# Display_Controller_VID2 register map
Vendor: Texas Instruments
Peripheral module from a debugger description file (folder omap36xx).
Registers are 32-bit, read-write, reset 0x0 unless marked. A register's access mark holds for its fields unless they carry their own. Offsets are as the file gives them; lines under a group give offsets from that group; [hi:lo] are bit positions; {n}, {i} and the like mark numbered series; 'fields as' and 'values as' point back to an identical list; <NAME> marks a mode.

## Display_Controller_VID2
0x14C DISPC_VIDn_BAj_0 — The register configures the base address of the video buffer for video window #n(#j for ping-pong mechanism with external trigger, based on the field polarity: 0 for even field and 1 for odd field).Shadow register, updated on VFP start period or EVSYNC.
  [31:0] VIDBA — Video base addressBase address of the video buffer (aligned on pixel size boundary)
0x150 DISPC_VIDn_BAj_1 — The register configures the base address of the video buffer for video window #n(#j for ping-pong mechanism with external trigger, based on the field polarity: 0 for even field and 1 for odd field).Shadow register, updated on VFP start period or EVSYNC.
  fields as DISPC_VIDn_BAj_0
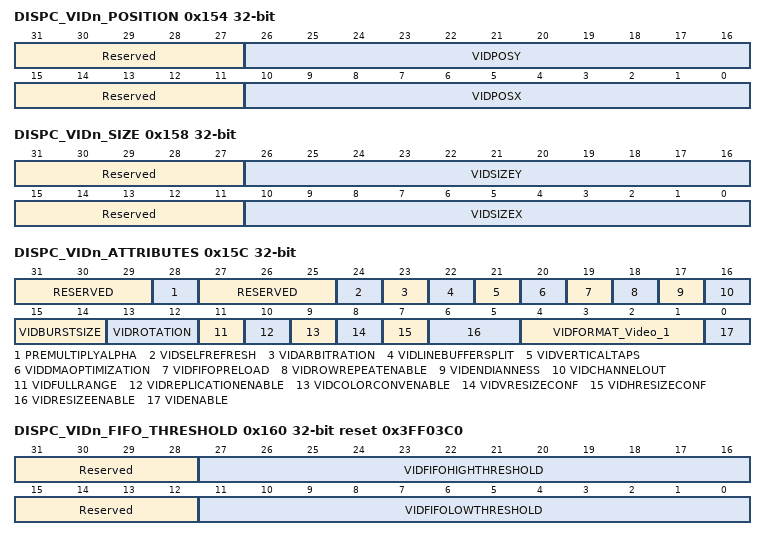
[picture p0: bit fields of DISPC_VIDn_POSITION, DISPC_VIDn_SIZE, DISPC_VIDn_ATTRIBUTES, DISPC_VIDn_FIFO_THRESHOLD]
0x154 DISPC_VIDn_POSITION — The register configures the position of video window #n.Shadow register, updated on VFP start period or EVSYNC.
  [31:27] Reserved — Write 0s for future compatibility.Read returns 0
  [26:16] VIDPOSY — Y position of video window #nEncoded value (from 0 to 2047) to specify the Y position of video window #n. The line at the top has the Y-position 0.
  [15:11] Reserved — Write 0s for future compatibility.Read returns 0
  [10:0] VIDPOSX — X position of video window #nEncoded value (from 0 to 2047) to specify the X position of video window #n. The first pixel on the left of the display screen has the X-position 0.
0x158 DISPC_VIDn_SIZE — The register configures the size of video window #n.Shadow register, updated on VFP start period or EVSYNC.
  [31:27] Reserved — Write 0s for future compatibility.Read returns 0
  [26:16] VIDSIZEY — Number of lines of video #nEncoded value (from 1 to 2048) to specify the number of lines of video window #n (program to value minus one).
  [15:11] Reserved — Write 0s for future compatibility.Read returns 0
  [10:0] VIDSIZEX — Number of pixels of video window #nEncoded value (from 1 to 2048) to specify the number of pixels of video window #n (program to value minus one).
0x15C DISPC_VIDn_ATTRIBUTES — The register configures the attributes of video window #n such as format, resizeenable, shadow register, updated on VFP start period, or EVSYNC.
  [31:29] RESERVED — Write 0s for future compatibility. Read returns 0.
  [28] PREMULTIPLYALPHA — The field configures the DISPC VID2 to process incoming data as pre-multiplied alpha data or non pre-multiplied alpha data.Default setting is non pre-multiplied alpha data.0x0: Non pre-multiplyalpha data color component 0x1: Premultiplyalpha data color component
  [27:25] RESERVED — Write 0s for future compatibility. Read returns 0.
  [24] VIDSELFREFRESH — Enables the self refresh of the video window from its own FIFO only.
    0=The video pipeline accesses the interconnect to fetch data from the system memory; 1=The video pipeline does not need anymore to fetch data from memory. Only the video FIFO is used. It takes effect after the frame has been loaded in the FIFO
  [23] VIDARBITRATION — Determines the priority of the video pipeline. The video pipeline is one of the high priority pipeline. The arbitration wheel gives always the priority first to the high priority pipelines using round-robin between them. When there is only normal priority pipelines sending requests, the round-robin applies between them.
    0=The video pipeline is one of the normal priority pipeline; 1=The video pipeline is one of the high priority pipeline
  [22] VIDLINEBUFFERSPLIT — Video vertical line buffer split
    0=Vertical line buffers are not split; 1=Vertical line buffers are split into two
  [21] VIDVERTICALTAPS — Video vertical resize tap number
    0=Three taps are used for the vertical filtering logic. The other two taps are not used.; 1=Five taps are used for the vertical filtering logic
  [20] VIDDMAOPTIMIZATION — Video optimization in case ofEven width is required for the input picture when 5 taps are used. .
    0=The DMA engine fetches one pixel for each 32-bit OCP request (RGB16 and YUV422) while doing 90- and 270-degree rotation (accessing on-chip memory and off-chip memory); 1=The DMA engine fetches two pixels for each 32-bit OCP request (RGB16 and YUV422) while doing 90- and 270-degree rotation (accessing on-chip memory and off-chip memory).The bit field [21] VIDVERTICALTAPS shall be set to 0x1, bit field [22] VIDLINEBUFFERSPLIT to 0x1, and all scaler registers shall be configured even for 1:1 ratio
  [19] VIDFIFOPRELOAD — Video preload value
    0=H/W prefetches pixels up to the preload value defined in the preload register; 1=H/W prefetches pixels up to the high threshold value
  [18] VIDROWREPEATENABLE — Video Row Repeat (YUV case only when rotating 90 or 270-degree)
    0=Row of VIDn won't be read twice; 1=The Row data are fetched twice to extract both the Y components
  [17] VIDENDIANNESS — Video Endianness
    0=Little endian operation is selected; 1=Big endian operation is selected
  [16] VIDCHANNELOUT — Video Channel Out configurationwr: Immediate
    0=LCD output selected; 1=24 bit output selected
  [15:14] VIDBURSTSIZE — Video DMA Burst Size
    0=4x32bit bursts; 1=8x32bit bursts; 2=16x32bit bursts
  [13:12] VIDROTATION — Video Rotation Flag
    0=No rotation or VidFormat is RGB; 1=Rotation by 90 degrees; 2=Rotation by 180 degrees; 3=Rotation by 270 degrees
  [11] VIDFULLRANGE
    0=Limited range selected: 16 subtracted from Y before color space conversion; 1=Full range selected: Y is not modified before the color space conversion
  [10] VIDREPLICATIONENABLE
    0=Disable Video replication logic; 1=Enable Video replication logic
  [9] VIDCOLORCONVENABLE
    0=Disable Color Space Conversion CbYCr to RGB; 1=Enable Color Space Conversion CbYCr to RGB
  [8] VIDVRESIZECONF — Video Vertical Resize Configuration
    0=Up-sampling selected; 1=Down-sampling selected
  [7] VIDHRESIZECONF — Video Horizontal Resize Configuration
    0=Up-sampling selected; 1=Down-sampling selected
  [6:5] VIDRESIZEENABLE — Video Resize Enable
    0=Disable the resize processing; 1=Enable the horizontal resize processing; 2=Enable the vertical resize processing; 3=Enable both horizontal and vertical resize processing
  [4:1] VIDFORMAT_Video_1 — Video1 channel Format; Other enums: Reserved (all other values between 0x0 and0x3,0x5, 0x7, and between 0xC and 0xF)VIDFORMAT(Video 2 channel) Video2 channel Format; Other enums: Reserved (all other values: 0x0 and0x3, 0x7, and 0xF) RW 0x0 .
    4=VIDFORMAT(Video 1 channel)_4 (RGB12 (16-bit container)); 6=VIDFORMAT(Video 1 channel)_6 (RGB 16); 8=VIDFORMAT(Video 1 channel)_8 (RGB 24 (unpacked in 32-bit container)); 9=VIDFORMAT(Video 1 channel)_9 (RGB 24 (packed in24-bit container)); 10=VIDFORMAT(Video 1 channel)_10 (YUV2 4:2:2 co-sited); 11=VIDFORMAT(Video 1 channel)_11 (UYVY 4:2:2 co-sited); 4=VIDFORMAT(Video 1 channel)_4 (RGB 12 (16-bit container)); 5=VIDFORMAT(Video 1 channel)_5 (ARGB 16); 6=VIDFORMAT(Video 1 channel)_6 (RGB 16); 8=VIDFORMAT(Video 1 channel)_8 (RGB 24 (un-packed in 32-bit container)); 9=VIDFORMAT(Video 1 channel)_9 (RGB 24 (packed in 24-bit container)); 10=VIDFORMAT(Video 1 channel)_10 (YUV2 4:2:2 co-sited); 11=VIDFORMAT(Video 1 channel)_11 (UYVY 4:2:2 co-sited); 12=VIDFORMAT(Video 1 channel)_12 (ARGB 32); 13=VIDFORMAT(Video 1 channel)_13 (RGBA 32); 14=VIDFORMAT(Video 1 channel)_14 (RGBx 32 (24-bit RGB aligned on MSB of the 32-bit container))
  [0] VIDENABLE
    0=Video disabled (video pipeline inactive and window not present); 1=Video enabled (video pipeline active and window present on the screen)
0x160 DISPC_VIDn_FIFO_THRESHOLD reset 0x3FF03C0 — The register configures the video FIFO associated with video pipeline #n.Shadow register, updated on VFP start period or EVSYNC.
  [31:28] Reserved — Write 0s for future compatibility. Read returns 0.
  [27:16] VIDFIFOHIGHTHRESHOLD — Video FIFO high thresholdNumber of bytes defining the threshold value
  [15:12] Reserved — Write 0s for future compatibility. Read returns 0.
  [11:0] VIDFIFOLOWTHRESHOLD — Video FIFO low thresholdNumber of bytes defining the threshold value
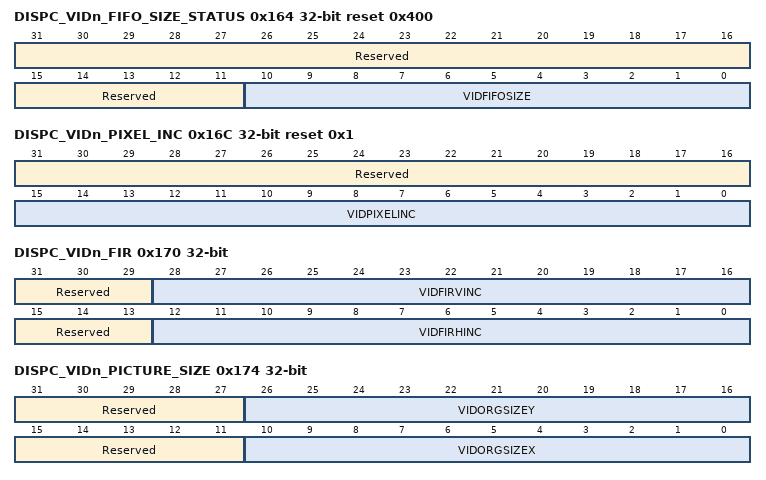
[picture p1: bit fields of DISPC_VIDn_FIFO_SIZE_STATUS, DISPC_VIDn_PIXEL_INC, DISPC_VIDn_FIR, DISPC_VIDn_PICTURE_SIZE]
0x164 DISPC_VIDn_FIFO_SIZE_STATUS ro reset 0x400 — The register defines the video FIFO size for video pipeline #n.
  [31:11] Reserved — Write 0s for future compatibility. Read returns 0.
  [10:0] VIDFIFOSIZE — Video FIFO SizeNumber of bytes defining the FIFO value
0x168 DISPC_VIDn_ROW_INC reset 0x1 — The register configures the number of bytes to increment at the end of the row for the buffer associated with video window #n.Shadow register, updated on VFP start period or EVSYNC.
  [31:0] VIDROWINC — Number of bytes to increment at the end of the rowEncoded signed value (from -2- 1 to 2) to specify the number of bytes to increment at the end of the row in the video buffer.The value 0 is invalid. The value 1 means next pixel. The value 1+n*BPP means increment of n pixels. The value 1- (n+1)*BPP means decrement of n pixels.
0x16C DISPC_VIDn_PIXEL_INC reset 0x1 — The register configures the number of bytes to increment between two pixels for the buffer associated with video window #n.Shadow register, updated on VFP start period or EVSYNC.
  [31:16] Reserved — Write 0s for future compatibility.Read returns 0
  [15:0] VIDPIXELINC — Number of bytes to increment at the end of the rowEncoded signed value (from -2- 1 to 2) to specify the number of bytes between two pixels in the video buffer.The value 0 is invalid. The value 1 means next pixel. The value 1+n*BPP means increment of n pixels. The value 1- (n+1)*BPP means decrement of n pixels
0x170 DISPC_VIDn_FIR — The register configures the resize factors for horizontal and vertical up-/down-sampling of video window #n.Shadow register, updated on VFP start period or EVSYNC.
  [31:29] Reserved — Write 0s for future compatibility. Read returns 0.
  [28:16] VIDFIRVINC — Vertical increment of the up/down-sampling filterEncoded value (from 1 to 4096). The value 0 is invalid. Values greater than 4096 are invalid.
  [15:13] Reserved — Write 0s for future compatibility. Read returns 0.
  [12:0] VIDFIRHINC — Horizontal increment of the up/down-sampling filterEncoded value (from 1 to 4096). The value 0 is invalid. Values greater than 4096 are invalid.
0x174 DISPC_VIDn_PICTURE_SIZE — The register configures the size of the video picture associated with video layer #nbefore up-/down-scaling.Shadow register, updated on VFP start period or EVSYNC.
  [31:27] Reserved — Write 0s for future compatibility.Read returns 0
  [26:16] VIDORGSIZEY — Number of lines of the video pictureEncoded value (from 1 to 2048) to specify the number of lines of the video picture in memory (program to value minus one).
  [15:11] Reserved — Write 0s for future compatibility.Read returns 0
  [10:0] VIDORGSIZEX — Number of pixels of the video pictureEncoded value (from 1 to 2048) to specify the number of pixels of the video picture in memory (program to value minus one). The size is limited to the size of the line buffer of the vertical sampling block in case the video picture is processed by the vertical filtering unit.
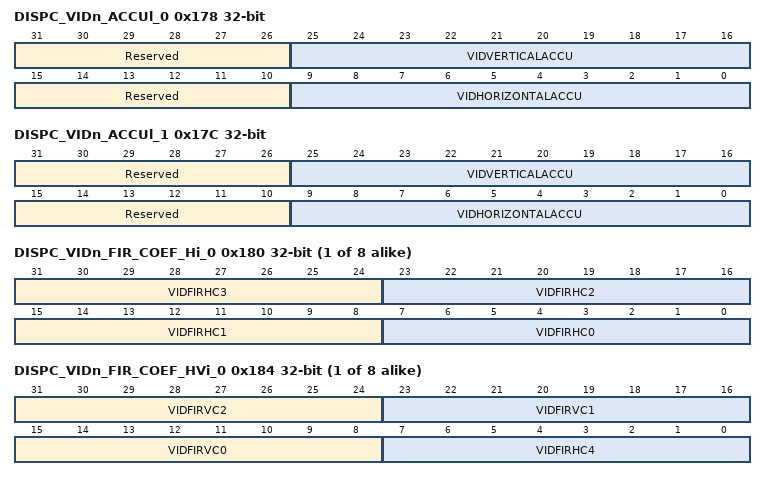
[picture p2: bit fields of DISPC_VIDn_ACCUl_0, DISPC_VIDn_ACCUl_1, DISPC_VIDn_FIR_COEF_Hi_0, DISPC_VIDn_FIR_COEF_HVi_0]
0x178 DISPC_VIDn_ACCUl_0 — The register configures the resize accumulator init values for horizontal and vertical up-/down-sampling of video window #n (#I for ping-pong mechanism with external trigger, based on the field polarity)Shadow register, updated on VFP start period or EVSYNC.
  [31:26] Reserved — Write 0s for future compatibility.Read returns 0
  [25:16] VIDVERTICALACCU — Vertical initialization accu value. Encoded value (from 0 to 1023).
  [15:10] Reserved — Write 0s for future compatibility.Read returns 0
  [9:0] VIDHORIZONTALACCU — Horizontal initialization accu value. Encoded value (from 0 to 1023).
0x17C DISPC_VIDn_ACCUl_1 — The register configures the resize accumulator init values for horizontal and vertical up-/down-sampling of video window #n (#I for ping-pong mechanism with external trigger, based on the field polarity)Shadow register, updated on VFP start period or EVSYNC.
  fields as DISPC_VIDn_ACCUl_0
{0x180+8i} DISPC_VIDn_FIR_COEF_Hi_{i} (i=0..7) — The bank of registers configure the up-/down-scaling coefficients for the vertical and horizontal resize of the video picture associated with video window #n for the phases from 0 to 7.Shadow register, updated on VFP start period or EVSYNC.
  [31:24] VIDFIRHC3 — Signed coefficient C3 for the horizontal up/down-scaling with the phase n
  [23:16] VIDFIRHC2 — Unsigned coefficient C2 for the horizontal up/down-scaling with the phase n
  [15:8] VIDFIRHC1 — Signed coefficient C1 for the horizontal up/down-scaling with the phase n
  [7:0] VIDFIRHC0 — Signed coefficient C0 for the horizontal up/down-scaling with the phase n
{0x184+8i} DISPC_VIDn_FIR_COEF_HVi_{i} (i=0..7) — The bank of registers configure the down/up-/down-scaling coefficients for the vertical and horizontal resize of the video picture associated with video window #n for the phases from 0 to 7.Shadow register, updated on VFP start period or EVSYNC.
  [31:24] VIDFIRVC2 — Signed coefficient C2 for the vertical up/down-scaling with the phase n
  [23:16] VIDFIRVC1 — Unsigned coefficient C1 for the vertical up/down-scaling with the phase n
  [15:8] VIDFIRVC0 — Signed coefficient C0 for the vertical up/down-scaling with the phase n
  [7:0] VIDFIRHC4 — Signed coefficient C4 for the horizontal up/down-scaling with the phase n
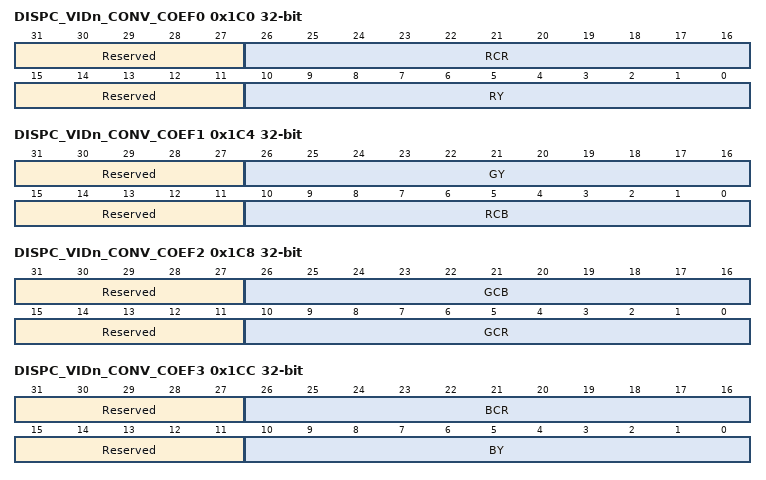
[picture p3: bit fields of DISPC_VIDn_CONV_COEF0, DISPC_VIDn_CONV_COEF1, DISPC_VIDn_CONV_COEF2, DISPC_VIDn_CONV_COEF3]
0x1C0 DISPC_VIDn_CONV_COEF0 — The register configures the color space conversion matrix coefficients for video pipeline #n.Shadow register, updated on VFP start period or EVSYNC.
  [31:27] Reserved — Write 0s for future compatibility.Read returns 0
  [26:16] RCR — RCr CoefficientEncoded signed value (from -1024 to 1023).
  [15:11] Reserved — Write 0s for future compatibility.Read returns 0
  [10:0] RY — RY CoefficientEncoded signed value (from -1024 to 1023).
0x1C4 DISPC_VIDn_CONV_COEF1 — The register configures the color space conversion matrix coefficients for video pipeline #n.Shadow register, updated on VFP start period or EVSYNC.
  [31:27] Reserved — Write 0s for future compatibility.Read returns 0
  [26:16] GY — GY CoefficientEncoded signed value (from -1024 to 1023).
  [15:11] Reserved — Write 0s for future compatibility.Read returns 0
  [10:0] RCB — RCb CoefficientEncoded signed value (from -1024 to 1023).
0x1C8 DISPC_VIDn_CONV_COEF2 — The register configures the color space conversion matrix coefficients for video pipeline #n.Shadow register, updated on VFP start period or EVSYNC.
  [31:27] Reserved — Write 0s for future compatibility.Read returns 0
  [26:16] GCB — GCb CoefficientEncoded signed value (from -1024 to 1023).
  [15:11] Reserved — Write 0s for future compatibility.Read returns 0
  [10:0] GCR — GCr CoefficientEncoded signed value (from -1024 to 1023).
0x1CC DISPC_VIDn_CONV_COEF3 — The register configures the color space conversion matrix coefficients for video pipeline #n.Shadow register, updated on VFP start period or EVSYNC.
  [31:27] Reserved — Write 0s for future compatibility.Read returns 0
  [26:16] BCR — BCr coefficientEncoded signed value (from -1024 to 1023).
  [15:11] Reserved — Write 0s for future compatibility.Read returns 0
  [10:0] BY — BY coefficientEncoded signed value (from -1024 to 1023).
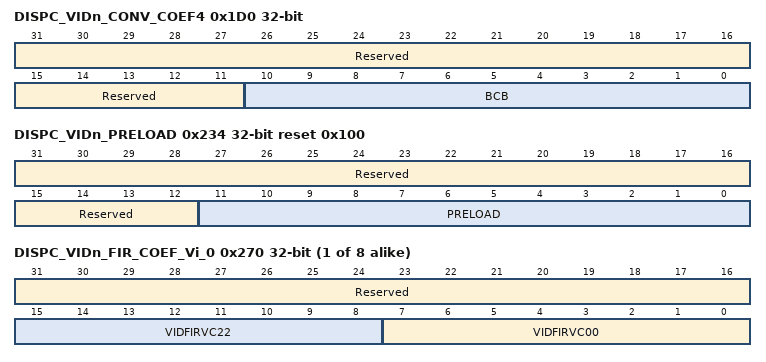
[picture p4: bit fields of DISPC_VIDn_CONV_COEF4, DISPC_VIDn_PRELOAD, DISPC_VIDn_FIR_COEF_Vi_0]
0x1D0 DISPC_VIDn_CONV_COEF4 — The register configures the color space conversion matrix coefficients for video pipeline #n.Shadow register, updated on VFP start period or EVSYNC.
  [31:11] Reserved — Write 0s for future compatibility.Read returns 0
  [10:0] BCB — BCb CoefficientEncoded signed value (from -1024 to 1023).
0x234 DISPC_VIDn_PRELOAD reset 0x100 — This register configures the video FIFO. Shadow register, updated on VFP start period or EVSYNC.
  [31:12] Reserved — Write 0s for future compatibility. Read returns 0.
  [11:0] PRELOAD — Video preload value: Number of bytes defining the preload value.Constraint: Maximum value is (FIFO size - DMA burst size - 8) bytes
{0x270+4i} DISPC_VIDn_FIR_COEF_Vi_{i} (i=0..7) — This bank of registers configures the down/up/down-scaling coefficients for the vertical resize of the video picture associated with video window #n for phases 0 to 7. Shadow register, updated on VFP start period or EVSYNC.
  [31:16] Reserved — Write 0s for future compatibility. Read returns 0.
  [15:8] VIDFIRVC22 — Signed coefficient C22 for vertical up/down-scaling with phase n
  [7:0] VIDFIRVC00 — Signed coefficient C00 for vertical up/down-scaling with phase n
